# STM32F405xx register map
File version: 1.0
Registers are 32-bit, read-write, reset 0x0 unless marked. A register's access mark holds for its fields unless they carry their own. Offsets are from the block's base; [hi:lo] are bit positions; {n}, {i} and the like mark numbered series; 'fields as' and 'values as' point back to an identical list.

## DMA1
Base 0x40026000
Same registers: DMA2 0x40026400
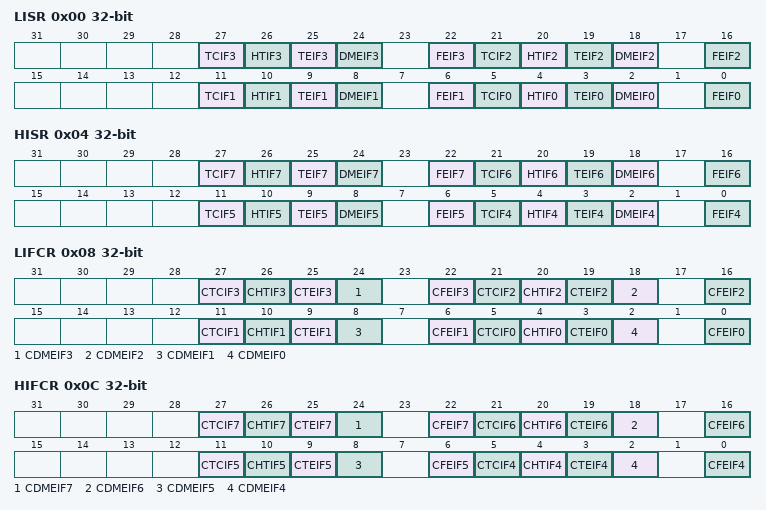
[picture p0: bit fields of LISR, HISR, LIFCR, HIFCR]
0x00 LISR — DMA low interrupt status register
  [27] TCIF3, [26] HTIF3, [25] TEIF3, [24] DMEIF3, [22] FEIF3, [21] TCIF2, [20] HTIF2, [19] TEIF2, [18] DMEIF2, [16] FEIF2, [11] TCIF1, [10] HTIF1, [9] TEIF1, [8] DMEIF1, [6] FEIF1, [5] TCIF0, [4] HTIF0, [3] TEIF0, [2] DMEIF0, [0] FEIF0
0x04 HISR — DMA high interrupt status register
  [27] TCIF7, [26] HTIF7, [25] TEIF7, [24] DMEIF7, [22] FEIF7, [21] TCIF6, [20] HTIF6, [19] TEIF6, [18] DMEIF6, [16] FEIF6, [11] TCIF5, [10] HTIF5, [9] TEIF5, [8] DMEIF5, [6] FEIF5, [5] TCIF4, [4] HTIF4, [3] TEIF4, [2] DMEIF4, [0] FEIF4
0x08 LIFCR — DMA low interrupt flag clear register
  [27] CTCIF3, [26] CHTIF3, [25] CTEIF3, [24] CDMEIF3, [22] CFEIF3, [21] CTCIF2, [20] CHTIF2, [19] CTEIF2, [18] CDMEIF2, [16] CFEIF2, [11] CTCIF1, [10] CHTIF1, [9] CTEIF1, [8] CDMEIF1, [6] CFEIF1, [5] CTCIF0, [4] CHTIF0, [3] CTEIF0, [2] CDMEIF0, [0] CFEIF0
0x0C HIFCR — DMA high interrupt flag clear register
  [27] CTCIF7, [26] CHTIF7, [25] CTEIF7, [24] CDMEIF7, [22] CFEIF7, [21] CTCIF6, [20] CHTIF6, [19] CTEIF6, [18] CDMEIF6, [16] CFEIF6, [11] CTCIF5, [10] CHTIF5, [9] CTEIF5, [8] CDMEIF5, [6] CFEIF5, [5] CTCIF4, [4] CHTIF4, [3] CTEIF4, [2] CDMEIF4, [0] CFEIF4
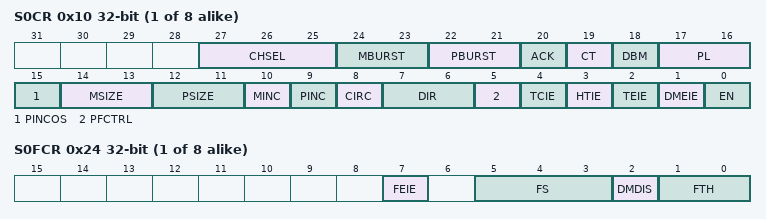
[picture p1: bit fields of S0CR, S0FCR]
{0x10+0x18*i} S{i}CR (i=0..7) — DMA stream x configuration register
  [27:25] CHSEL, [24:23] MBURST, [22:21] PBURST, [20] ACK, [19] CT, [18] DBM, [17:16] PL, [15] PINCOS, [14:13] MSIZE, [12:11] PSIZE, [10] MINC, [9] PINC, [8] CIRC, [7:6] DIR, [5] PFCTRL, [4] TCIE, [3] HTIE, [2] TEIE, [1] DMEIE, [0] EN
{0x14+0x18*i} S{i}NDTR (i=0..7) — DMA stream x number of data register
  [15:0] SxNDT
{0x18+0x18*i} S{i}PAR (i=0..7) — DMA stream x peripheral address register
  [31:0] PA — Peripheral Address
{0x1C+0x18*i} S{i}M0AR (i=0..7) — DMA stream x memory 0 address register
  [31:0] M0A — Memory Address
{0x20+0x18*i} S{i}M1AR (i=0..7) — DMA stream x memory 1 address register
  [31:0] M1A — Memory Address
{0x24+0x18*i} S{i}FCR (i=0..7) — DMA stream x FIFO control register
  [7] FEIE, [5:3] FS, [2] DMDIS, [1:0] FTH

## RNG
Base 0x50060800
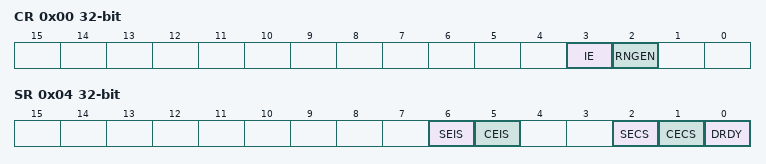
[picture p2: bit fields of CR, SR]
0x00 CR — RNG control register
  [3] IE, [2] RNGEN
0x04 SR — RNG status register
  [6] SEIS, [5] CEIS, [2] SECS, [1] CECS, [0] DRDY
0x08 DR — RNG data register

## FSMC
Base 0xA0000000
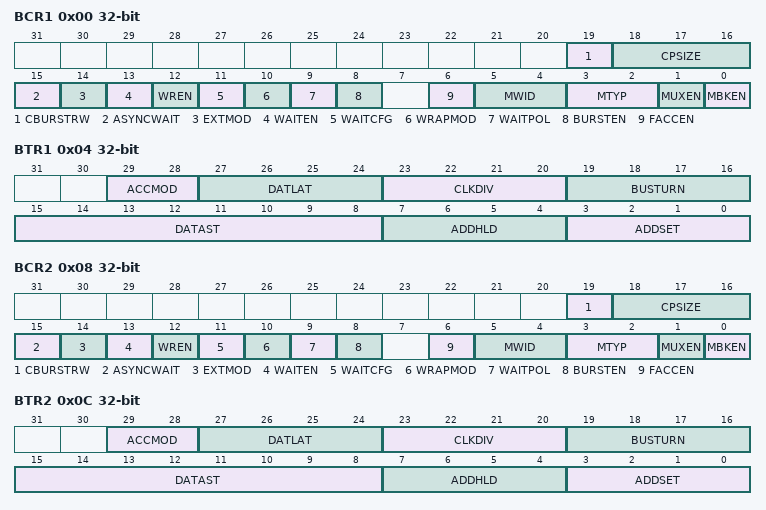
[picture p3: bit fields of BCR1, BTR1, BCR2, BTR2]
0x00 BCR1 — NOR/PSRAM chip-select control register(BCR) and chip-select timing register(BTR)
  [19] CBURSTRW — Write burst enable
  [18:16] CPSIZE — CRAM page size
  [15] ASYNCWAIT — Asynchronous wait
  [14] EXTMOD — Extended mode enable
  [13] WAITEN — Wait enable bit
  [12] WREN — Write enable bit
  [11] WAITCFG — Wait timing configuration
  [10] WRAPMOD — Wrapped burst mode support
  [9] WAITPOL — Wait signal polarity bit
  [8] BURSTEN — Burst enable bit
  [6] FACCEN — Flash access enable
  [5:4] MWID — MWID[1:0] bits (Memory data bus width)
  [3:2] MTYP — MTYP[1:0] bits (Memory type)
  [1] MUXEN — Address/data multiplexing enable bit
  [0] MBKEN — Memory bank enable bit
0x04 BTR1 — NOR/PSRAM chip-select control register(BCR) and chip-select timing register(BTR)
  [29:28] ACCMOD — ACCMOD[1:0] bits (Access mode)
  [27:24] DATLAT — DATLA[3:0] bits (Data latency)
  [23:20] CLKDIV — CLKDIV[3:0] bits (Clock divide ratio)
  [19:16] BUSTURN — BUSTURN[3:0] bits (Bus turnaround phase duration)
  [15:8] DATAST — DATAST [7:0] bits (Data-phase duration)
  [7:4] ADDHLD — ADDHLD[3:0] bits (Address-hold phase duration)
  [3:0] ADDSET — ADDSET[3:0] bits (Address setup phase duration)
0x08 BCR2 — NOR/PSRAM chip-select control register(BCR) and chip-select timing register(BTR)
  fields as BCR1
0x0C BTR2 — NOR/PSRAM chip-select control register(BCR) and chip-select timing register(BTR)
  fields as BTR1
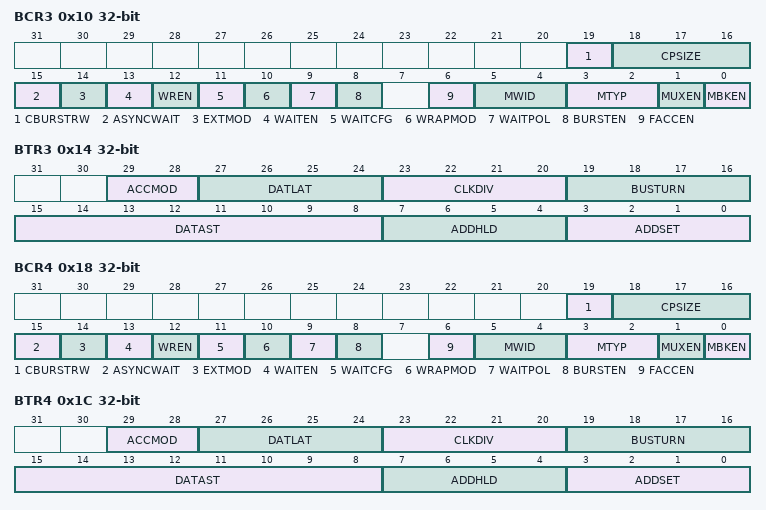
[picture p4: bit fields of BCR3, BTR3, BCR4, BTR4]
0x10 BCR3 — NOR/PSRAM chip-select control register(BCR) and chip-select timing register(BTR)
  fields as BCR1
0x14 BTR3 — NOR/PSRAM chip-select control register(BCR) and chip-select timing register(BTR)
  fields as BTR1
0x18 BCR4 — NOR/PSRAM chip-select control register(BCR) and chip-select timing register(BTR)
  fields as BCR1
0x1C BTR4 — NOR/PSRAM chip-select control register(BCR) and chip-select timing register(BTR)
  fields as BTR1
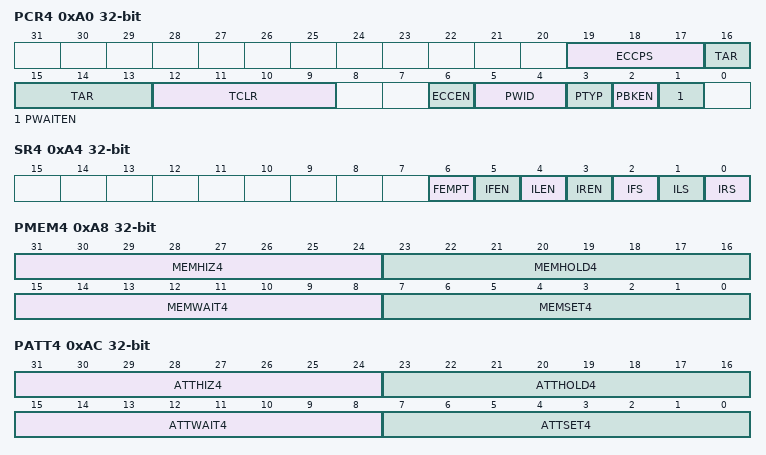
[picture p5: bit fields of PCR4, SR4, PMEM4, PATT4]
0xA0 PCR4 — PC Card control register 4
  [19:17] ECCPS — ECCPS[2:0] bits (ECC page size)
  [16:13] TAR — TAR[3:0] bits (ALE to RE delay)
  [12:9] TCLR — TCLR[3:0] bits (CLE to RE delay)
  [6] ECCEN — ECC computation logic enable bit
  [5:4] PWID — PWID[1:0] bits (NAND Flash databus width)
  [3] PTYP — Memory type
  [2] PBKEN — PC Card/NAND Flash memory bank enable bit
  [1] PWAITEN — Wait feature enable bit
0xA4 SR4 — PC Card FIFO status and interrupt register 4
  [6] FEMPT — FIFO empty
  [5] IFEN — Interrupt Falling Edge detection Enable bit
  [4] ILEN — Interrupt Level detection Enable bit
  [3] IREN — Interrupt Rising Edge detection Enable bit
  [2] IFS — Interrupt Falling Edge status
  [1] ILS — Interrupt Level status
  [0] IRS — Interrupt Rising Edge status
0xA8 PMEM4 — PC Card Common memory space timing register 4
  [31:24] MEMHIZ4 — MEMHIZ4[7:0] bits (Common memory 4 databus HiZ time)
  [23:16] MEMHOLD4 — MEMHOLD4[7:0] bits (Common memory 4 hold time)
  [15:8] MEMWAIT4 — MEMWAIT4[7:0] bits (Common memory 4 wait time)
  [7:0] MEMSET4 — MEMSET4[7:0] bits (Common memory 4 setup time)
0xAC PATT4 — PC Card Attribute memory space timing register 4
  [31:24] ATTHIZ4 — ATTHIZ4[7:0] bits (Attribute memory 4 databus HiZ time)
  [23:16] ATTHOLD4 — ATTHOLD4[7:0] bits (Attribute memory 4 hold time)
  [15:8] ATTWAIT4 — ATTWAIT4[7:0] bits (Attribute memory 4 wait time)
  [7:0] ATTSET4 — ATTSET4[7:0] bits (Attribute memory 4 setup time)
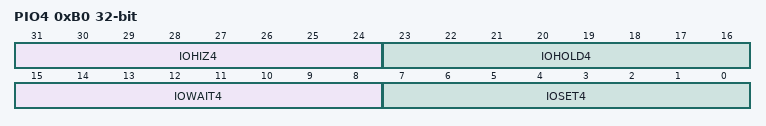
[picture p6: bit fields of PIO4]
0xB0 PIO4 — PC Card I/O space timing register 4
  [31:24] IOHIZ4 — IOHIZ4[7:0] bits (I/O 4 databus HiZ time)
  [23:16] IOHOLD4 — IOHOLD4[7:0] bits (I/O 4 hold time)
  [15:8] IOWAIT4 — IOWAIT4[7:0] bits (I/O 4 wait time)
  [7:0] IOSET4 — IOSET4[7:0] bits (I/O 4 setup time)
